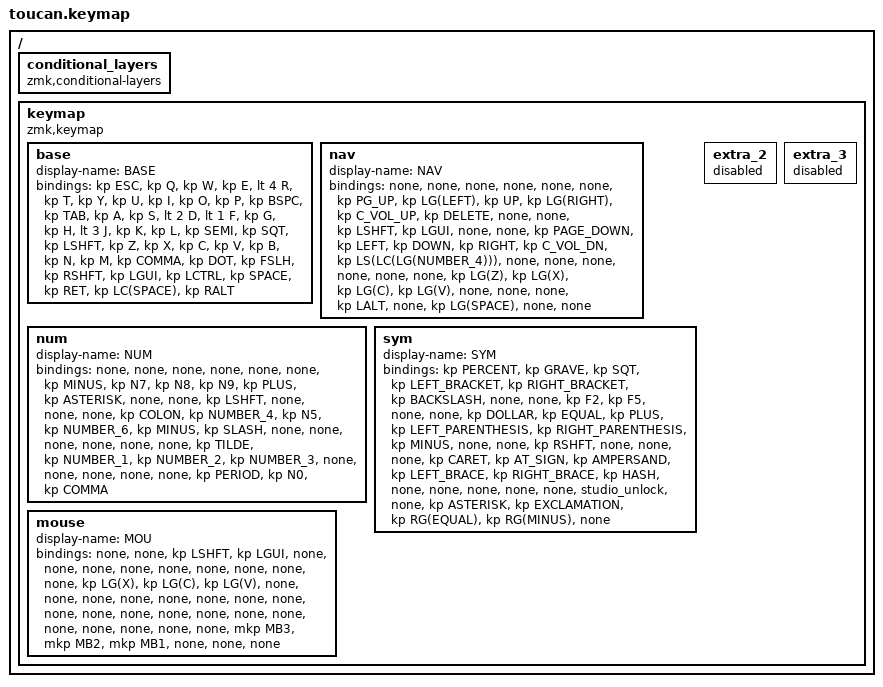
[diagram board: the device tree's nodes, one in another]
#include <behaviors.dtsi>
#include <dt-bindings/zmk/keys.h>
#include <dt-bindings/zmk/pointing.h>

#define BASE 0
#define NAV  1
#define SYM  2
#define ADJ  3

/ {
    conditional_layers { compatible = "zmk,conditional-layers"; };

    keymap {
        compatible = "zmk,keymap";

        base {
            display-name = "BASE";
            bindings = <
&kp ESC  &kp Q  &kp W  &kp E  &lt 4 R  &kp T  &kp Y  &kp U  &kp I  &kp O  &kp P  &kp BSPC  &kp TAB  &kp A  &kp S  &lt 2 D  &lt 1 F  &kp G  &kp H  &lt 3 J  &kp K  &kp L  &kp SEMI  &kp SQT  &kp LSHFT  &kp Z  &kp X  &kp C  &kp V  &kp B  &kp N  &kp M  &kp COMMA  &kp DOT  &kp FSLH  &kp RSHFT  &kp LGUI  &kp LCTRL  &kp SPACE  &kp RET  &kp LC(SPACE)  &kp RALT
            >;
        };

        nav {
            display-name = "NAV";
            bindings = <
&none  &none  &none  &none  &none  &none  &kp PG_UP  &kp LG(LEFT)  &kp UP  &kp LG(RIGHT)  &kp C_VOL_UP  &kp DELETE  &none  &none  &kp LSHFT  &kp LGUI  &none  &none  &kp PAGE_DOWN  &kp LEFT  &kp DOWN  &kp RIGHT  &kp C_VOL_DN  &kp LS(LC(LG(NUMBER_4)))  &none  &none  &none  &none  &none  &none  &kp LG(Z)  &kp LG(X)  &kp LG(C)  &kp LG(V)  &none  &none  &none  &kp LALT  &none  &kp LG(SPACE)  &none  &none
            >;
        };

        num {
            display-name = "NUM";
            bindings = <
&none  &none  &none  &none  &none  &none  &kp MINUS  &kp N7  &kp N8  &kp N9  &kp PLUS  &kp ASTERISK  &none  &none  &kp LSHFT  &none  &none  &none  &kp COLON  &kp NUMBER_4  &kp N5  &kp NUMBER_6  &kp MINUS  &kp SLASH  &none  &none  &none  &none  &none  &none  &kp TILDE  &kp NUMBER_1  &kp NUMBER_2  &kp NUMBER_3  &none  &none  &none  &none  &none  &kp PERIOD  &kp N0  &kp COMMA
            >;
        };

        sym {
            display-name = "SYM";
            bindings = <
&kp PERCENT  &kp GRAVE  &kp SQT  &kp LEFT_BRACKET  &kp RIGHT_BRACKET  &kp BACKSLASH  &none  &none  &kp F2  &kp F5  &none  &none  &kp DOLLAR  &kp EQUAL  &kp PLUS  &kp LEFT_PARENTHESIS  &kp RIGHT_PARENTHESIS  &kp MINUS  &none  &none  &kp RSHFT  &none  &none  &none  &kp CARET  &kp AT_SIGN  &kp AMPERSAND  &kp LEFT_BRACE  &kp RIGHT_BRACE  &kp HASH  &none  &none  &none  &none  &none  &studio_unlock  &none  &kp ASTERISK  &kp EXCLAMATION  &kp RG(EQUAL)  &kp RG(MINUS)  &none
            >;
        };

        mouse {
            display-name = "MOU";
            bindings = <
&none  &none  &kp LSHFT  &kp LGUI  &none  &none  &none  &none  &none  &none  &none  &none  &none  &kp LG(X)  &kp LG(C)  &kp LG(V)  &none  &none  &none  &none  &none  &none  &none  &none  &none  &none  &none  &none  &none  &none  &none  &none  &none  &none  &none  &none  &mkp MB3  &mkp MB2  &mkp MB1  &none  &none  &none
            >;
        };

        extra_2 { status = "reserved"; };

        extra_3 { status = "reserved"; };
    };
};
